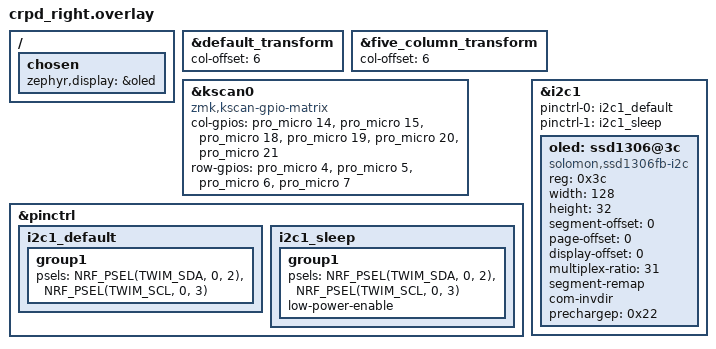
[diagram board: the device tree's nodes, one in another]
#include "crpd.dtsi"

&default_transform {
  col-offset = <6>;
};

&five_column_transform {
  col-offset = <6>;
};

&kscan0 {
  compatible = "zmk,kscan-gpio-matrix";

  col-gpios = <&pro_micro 14 GPIO_ACTIVE_HIGH>,
              <&pro_micro 15 GPIO_ACTIVE_HIGH>,
              <&pro_micro 18 GPIO_ACTIVE_HIGH>,
              <&pro_micro 19 GPIO_ACTIVE_HIGH>,
              <&pro_micro 20 GPIO_ACTIVE_HIGH>,
              <&pro_micro 21 GPIO_ACTIVE_HIGH>;

  row-gpios = <&pro_micro 4 (GPIO_ACTIVE_HIGH | GPIO_PULL_DOWN)>,
              <&pro_micro 5 (GPIO_ACTIVE_HIGH | GPIO_PULL_DOWN)>,
              <&pro_micro 6 (GPIO_ACTIVE_HIGH | GPIO_PULL_DOWN)>,
              <&pro_micro 7 (GPIO_ACTIVE_HIGH | GPIO_PULL_DOWN)>;
};

 / {
   chosen {
     zephyr,display = &oled;
   };
 };

 &pinctrl {
   i2c1_default: i2c1_default {
     group1 {
       psels = <NRF_PSEL(TWIM_SDA, 0, 2)>, <NRF_PSEL(TWIM_SCL, 0, 3)>;
     };
   };
   i2c1_sleep: i2c1_sleep {
     group1 {
       psels = <NRF_PSEL(TWIM_SDA, 0, 2)>, <NRF_PSEL(TWIM_SCL, 0, 3)>;
       low-power-enable;
     };
   };
 };

 &i2c1 {
   status = "okay";
   pinctrl-0 = <&i2c1_default>;
   pinctrl-1 = <&i2c1_sleep>;
   pinctrl-names = "default", "sleep";

   oled: ssd1306@3c {
     compatible = "solomon,ssd1306fb-i2c";
     reg = <0x3c>;
     width = <128>;
     height = <32>;
     segment-offset = <0>;
     page-offset = <0>;
     display-offset = <0>;
     multiplex-ratio = <31>;
     segment-remap;
     com-invdir;
     prechargep = <0x22>;
   };
 };
